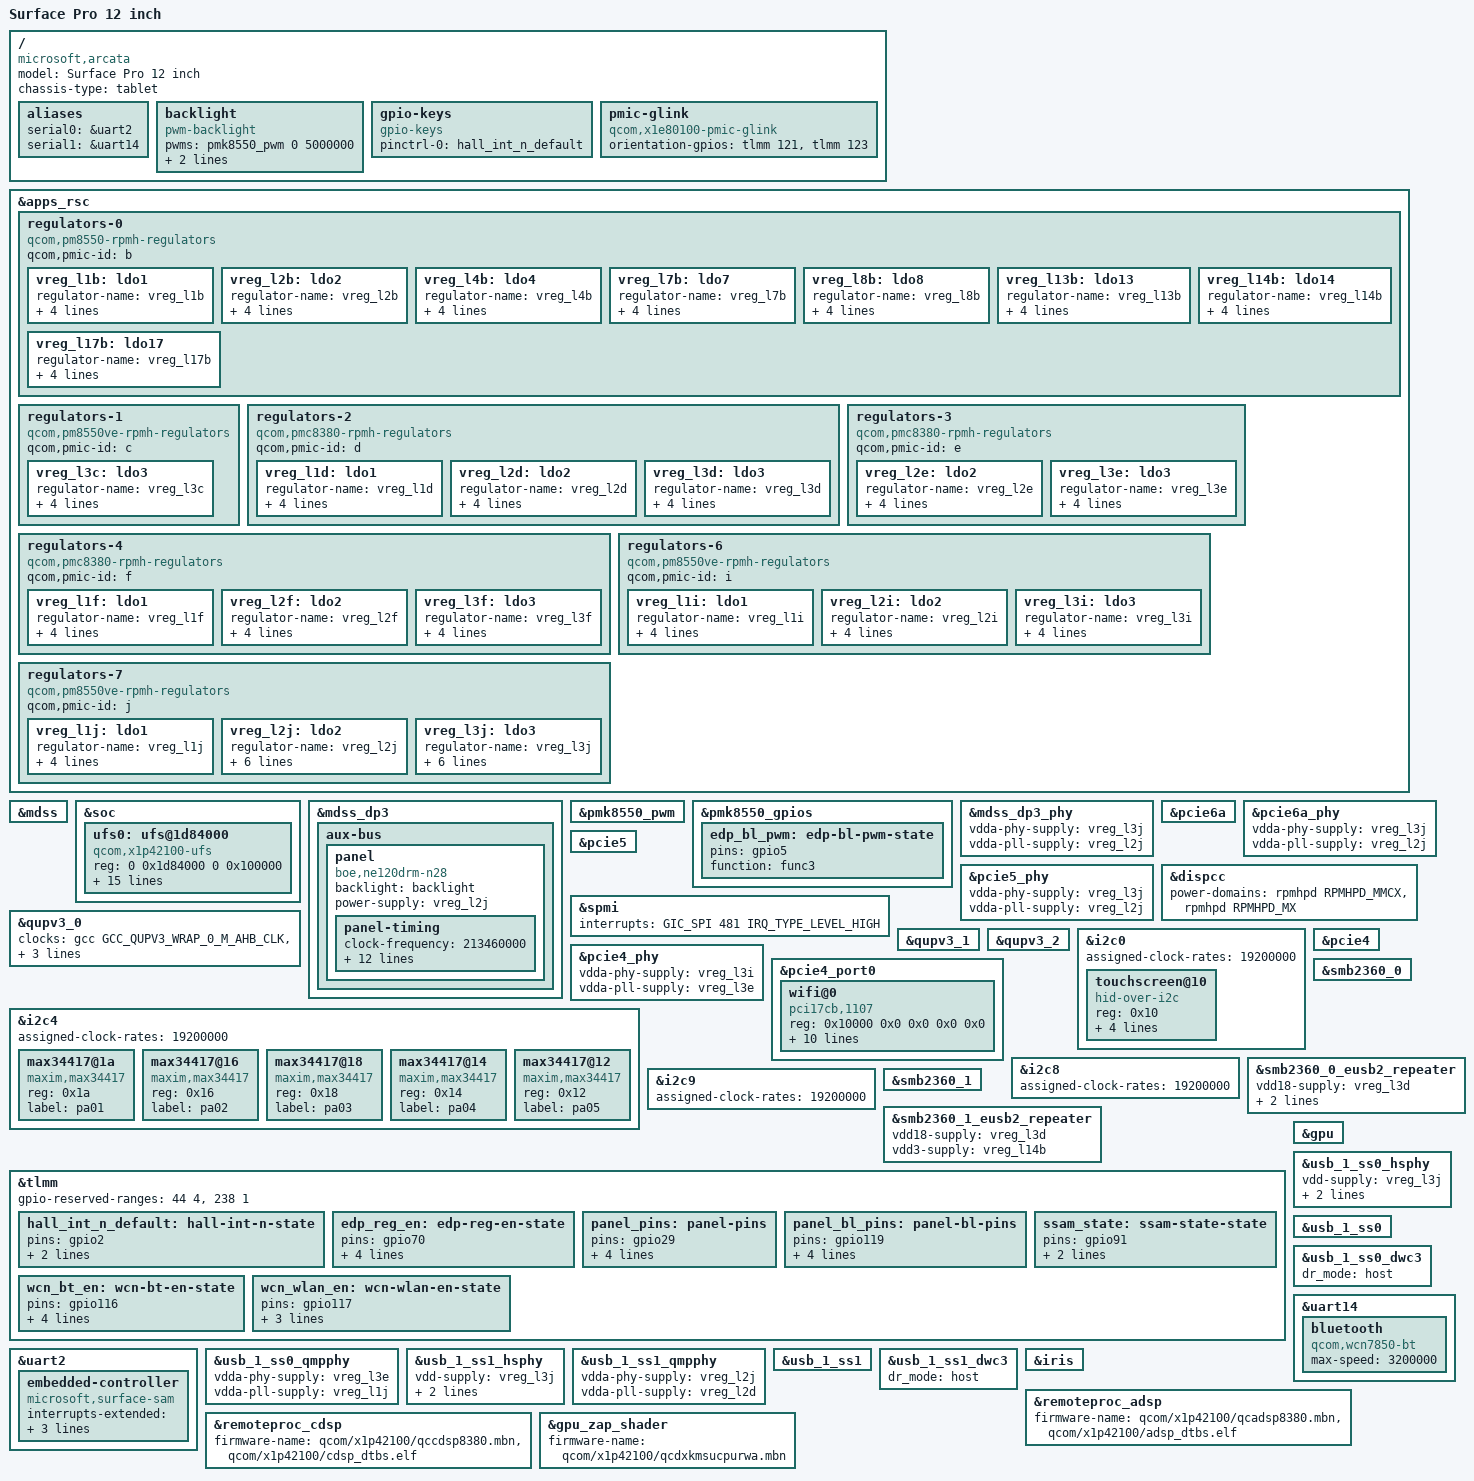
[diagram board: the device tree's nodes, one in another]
// SPDX-License-Identifier: BSD-3-Clause
/*
 * Copyright (c) 2023 Qualcomm Innovation Center, Inc. All rights reserved.
 * Copyright (c) 2024, Xilin Wu <wuxilin123@gmail.com>
 * Copyright (c) 2025 Dale Whinham <daleyo@gmail.com>
 * Copyright (c) 2025 Harrison Vanderbyl <harrison.vanderbyl@gmail.com>
 */

/dts-v1/;

#include <dt-bindings/gpio/gpio.h>
#include <dt-bindings/input/gpio-keys.h>
#include <dt-bindings/input/input.h>
#include <dt-bindings/pinctrl/qcom,pmic-gpio.h>
#include <dt-bindings/regulator/qcom,rpmh-regulator.h>

#include "x1p42100.dtsi"
#include "x1e80100-pmics.dtsi"



/ {
	model = "Surface Pro 12 inch";
	compatible = "microsoft,arcata", "qcom,x1p42100";
	chassis-type = "tablet";

	aliases {
		serial0 = &uart2;
		serial1 = &uart14;
	};
	
	backlight: backlight {
		compatible = "pwm-backlight";
		pwms = <&pmk8550_pwm 0 5000000>;
		enable-gpios = <&pmc8380_3_gpios 4 GPIO_ACTIVE_HIGH>;

		pinctrl-0 = <&panel_bl_pins>, <&edp_bl_pwm>;
		pinctrl-names = "default";

	};

	gpio-keys {
		compatible = "gpio-keys";

		pinctrl-0 = <&hall_int_n_default>;
		pinctrl-names = "default";

	};


	pmic-glink {
		compatible = "qcom,x1e80100-pmic-glink",
			     "qcom,pmic-glink";
		#address-cells = <1>;
		#size-cells = <0>;
		orientation-gpios = <&tlmm 121 GPIO_ACTIVE_HIGH>,
				    <&tlmm 123 GPIO_ACTIVE_HIGH>;

	
	
	
	};


	
};



&apps_rsc {
	regulators-0 {
		compatible = "qcom,pm8550-rpmh-regulators";
		qcom,pmic-id = "b";

		vreg_l1b: ldo1 {
			regulator-name = "vreg_l1b";
			regulator-min-microvolt = <1800000>;
			regulator-max-microvolt = <1800000>;
			regulator-initial-mode = <RPMH_REGULATOR_MODE_HPM>;
		};

		vreg_l2b: ldo2 {
			regulator-name = "vreg_l2b";
			regulator-min-microvolt = <3072000>;
			regulator-max-microvolt = <3072000>;
			regulator-initial-mode = <RPMH_REGULATOR_MODE_HPM>;
		};

		vreg_l4b: ldo4 {
			regulator-name = "vreg_l4b";
			regulator-min-microvolt = <1800000>;
			regulator-max-microvolt = <1800000>;
			regulator-initial-mode = <RPMH_REGULATOR_MODE_HPM>;
		};
		vreg_l7b: ldo7 {
			regulator-name = "vreg_l7b";
			regulator-min-microvolt = <2800000>;
			regulator-max-microvolt = <2800000>;
			regulator-initial-mode = <RPMH_REGULATOR_MODE_HPM>;
		};

		vreg_l8b: ldo8 {
			regulator-name = "vreg_l8b";
			regulator-min-microvolt = <3072000>;
			regulator-max-microvolt = <3072000>;
			regulator-initial-mode = <RPMH_REGULATOR_MODE_HPM>;
		};


		vreg_l13b: ldo13 {
			regulator-name = "vreg_l13b";
			regulator-min-microvolt = <3072000>;
			regulator-max-microvolt = <3072000>;
			regulator-initial-mode = <RPMH_REGULATOR_MODE_HPM>;
		};

		vreg_l14b: ldo14 {
			regulator-name = "vreg_l14b";
			regulator-min-microvolt = <3072000>;
			regulator-max-microvolt = <3072000>;
			regulator-initial-mode = <RPMH_REGULATOR_MODE_HPM>;
		};

		vreg_l17b: ldo17 {
			regulator-name = "vreg_l17b";
			regulator-min-microvolt = <2800000>; /* Assuming a common voltage */
			regulator-max-microvolt = <2800000>; /* Assuming a common voltage */
			regulator-initial-mode = <RPMH_REGULATOR_MODE_HPM>;
		};
	};

	regulators-1 {
		compatible = "qcom,pm8550ve-rpmh-regulators";
		qcom,pmic-id = "c";

		vreg_l3c: ldo3 {
			regulator-name = "vreg_l3c";
			regulator-min-microvolt = <912000>;
			regulator-max-microvolt = <912000>;
			regulator-initial-mode = <RPMH_REGULATOR_MODE_HPM>;
		};
	};

	regulators-2 {
		compatible = "qcom,pmc8380-rpmh-regulators";
		qcom,pmic-id = "d";

		vreg_l1d: ldo1 {
			regulator-name = "vreg_l1d";
			regulator-min-microvolt = <880000>;
			regulator-max-microvolt = <880000>;
			regulator-initial-mode = <RPMH_REGULATOR_MODE_HPM>;
		};
		
		vreg_l2d: ldo2 {
			regulator-name = "vreg_l2d";
			regulator-min-microvolt = <912000>;
			regulator-max-microvolt = <912000>;
			regulator-initial-mode = <RPMH_REGULATOR_MODE_HPM>;
		};

		vreg_l3d: ldo3 {
			regulator-name = "vreg_l3d";
			regulator-min-microvolt = <1800000>;
			regulator-max-microvolt = <1800000>;
			regulator-initial-mode = <RPMH_REGULATOR_MODE_HPM>;
		};
	};

	regulators-3 {
		compatible = "qcom,pmc8380-rpmh-regulators";
		qcom,pmic-id = "e";

		vreg_l2e: ldo2 {
			regulator-name = "vreg_l2e";
			regulator-min-microvolt = <880000>;
			regulator-max-microvolt = <880000>;
			regulator-initial-mode = <RPMH_REGULATOR_MODE_HPM>;
		};

		vreg_l3e: ldo3 {
			regulator-name = "vreg_l3e";
			regulator-min-microvolt = <1200000>;
			regulator-max-microvolt = <1200000>;
			regulator-initial-mode = <RPMH_REGULATOR_MODE_HPM>;
		};
	};

	regulators-4 {
		compatible = "qcom,pmc8380-rpmh-regulators";
		qcom,pmic-id = "f";


		vreg_l1f: ldo1 {
			regulator-name = "vreg_l1f";
			regulator-min-microvolt = <1024000>;
			regulator-max-microvolt = <1024000>;
			regulator-initial-mode = <RPMH_REGULATOR_MODE_HPM>;
		};

		vreg_l2f: ldo2 {
			regulator-name = "vreg_l2f";
			regulator-min-microvolt = <1024000>;
			regulator-max-microvolt = <1024000>;
			regulator-initial-mode = <RPMH_REGULATOR_MODE_HPM>;
		};

		vreg_l3f: ldo3 {
			regulator-name = "vreg_l3f";
			regulator-min-microvolt = <1024000>;
			regulator-max-microvolt = <1024000>;
			regulator-initial-mode = <RPMH_REGULATOR_MODE_HPM>;
		};
	};

	regulators-6 {
		compatible = "qcom,pm8550ve-rpmh-regulators";
		qcom,pmic-id = "i";


		vreg_l1i: ldo1 {
			regulator-name = "vreg_l1i";
			regulator-min-microvolt = <1800000>;
			regulator-max-microvolt = <1800000>;
			regulator-initial-mode = <RPMH_REGULATOR_MODE_HPM>;
		};

		vreg_l2i: ldo2 {
			regulator-name = "vreg_l2i";
			regulator-min-microvolt = <1200000>;
			regulator-max-microvolt = <1200000>;
			regulator-initial-mode = <RPMH_REGULATOR_MODE_HPM>;
		};

		vreg_l3i: ldo3 {
			regulator-name = "vreg_l3i";
			regulator-min-microvolt = <880000>;
			regulator-max-microvolt = <880000>;
			regulator-initial-mode = <RPMH_REGULATOR_MODE_HPM>;
		};
	};

	regulators-7 {
		compatible = "qcom,pm8550ve-rpmh-regulators";
		qcom,pmic-id = "j";


		vreg_l1j: ldo1 {
			regulator-name = "vreg_l1j";
			regulator-min-microvolt = <912000>;
			regulator-max-microvolt = <912000>;
			regulator-initial-mode = <RPMH_REGULATOR_MODE_HPM>;
		};

		vreg_l2j: ldo2 {
			regulator-name = "vreg_l2j";
			regulator-min-microvolt = <1256000>;
			regulator-max-microvolt = <1256000>;
			regulator-initial-mode = <RPMH_REGULATOR_MODE_HPM>;
			regulator-boot-on;
			regulator-always-on;
		};

		vreg_l3j: ldo3 {
			regulator-name = "vreg_l3j";
			regulator-min-microvolt = <880000>;
			regulator-max-microvolt = <880000>;
			regulator-initial-mode = <RPMH_REGULATOR_MODE_HPM>;
			regulator-boot-on;
			regulator-always-on;
		};
	};

	
};

&mdss {
	status = "okay";
	
	
};






&soc {
	ufs0: ufs@1d84000 {
		compatible = "qcom,x1p42100-ufs", "qcom,ufs-qcom";
		reg = <0 0x1d84000 0 0x100000>;
		interrupts = <GIC_SPI 265 IRQ_TYPE_LEVEL_HIGH>; /* Placeholder interrupt */

		clocks = <&gcc GCC_UFS_PHY_AXI_CLK>,
				 <&gcc GCC_UFS_PHY_UNIPRO_CORE_CLK>,
				 <&gcc GCC_UFS_PHY_ICE_CORE_CLK>,
				 <&gcc GCC_AGGRE_UFS_PHY_AXI_CLK>,
				 <&gcc GCC_UFS_PHY_AHB_CLK>,
				 <&gcc GCC_UFS_PHY_PHY_AUX_CLK>,
				 <&gcc GCC_UFS_PHY_TX_SYMBOL_0_CLK>,
				 <&gcc GCC_UFS_PHY_RX_SYMBOL_0_CLK>,
				 <&gcc GCC_UFS_PHY_RX_SYMBOL_1_CLK>,
				 <&tcsr TCSR_UFS_PHY_CLKREF_EN>;
		clock-names = "core_clk", "unipro_core_clk", "ice_core_clk",
					  "aggre_axi_clk", "ahb_clk", "phy_aux_clk",
					  "tx_symbol_0_clk", "rx_symbol_0_clk", "rx_symbol_1_clk",
					  "clkref_en";

		


		vcc-supply = <&vreg_l3j>;
		vcc-max-supply = <&vreg_l17b>;
		vccq-supply = <&vreg_l2i>;
		vccq2-supply = <&vreg_l3e>;

		status = "okay";
	};
};

&mdss_dp3 {
	/delete-property/ #sound-dai-cells;

	status = "okay";

   


        aux-bus {
			panel: panel {
				compatible = "boe,ne120drm-n28", "panel-edp";

				// GPIOs based on display.txt
				
				backlight = <&backlight>;
				power-supply = <&vreg_l2j>;   // J2: 1.256V (corner 7)

				
				// Panel timing based on display.txt
				panel-timing {
					clock-frequency = <213460000>; // Hz
					hactive = <2196>;
					vactive = <1464>;
					hfront-porch = <32>;
					hback-porch = <80>;
					hsync-len = <10>;
					vfront-porch = <8>;
					vback-porch = <12>;
					vsync-len = <4>;
					hsync-active = <0>;
					vsync-active = <0>;
					de-active = <1>;
					pixelclk-active = <0>;
				};

				
			};
		};
	
	
	
	
	};




&pmk8550_pwm {
	status = "okay";
};

&pmk8550_gpios {
	edp_bl_pwm: edp-bl-pwm-state {
		pins = "gpio5";
		function = "func3";
	};
};

&mdss_dp3_phy {
	vdda-phy-supply = <&vreg_l3j>;
	vdda-pll-supply = <&vreg_l2j>;


	status = "okay";
};

&pcie6a {
	status = "okay";
};

&pcie6a_phy {
	vdda-phy-supply = <&vreg_l3j>;
	vdda-pll-supply = <&vreg_l2j>;

	status = "okay";
};

&pcie5 {
	status = "okay";
};
&pcie5_phy {
	vdda-phy-supply = <&vreg_l3j>;
	vdda-pll-supply = <&vreg_l2j>;

	status = "okay";
};


&dispcc {
	power-domains = <&rpmhpd RPMHPD_MMCX>,
					<&rpmhpd RPMHPD_MX>;
	status = "okay";
};

&spmi {
	interrupt-names = "periph_irq";
	interrupts = <GIC_SPI 481 IRQ_TYPE_LEVEL_HIGH>;
};


&qupv3_0 {
	status = "okay";
	clocks = <&gcc GCC_QUPV3_WRAP_0_M_AHB_CLK>,
					<&gcc GCC_QUPV3_WRAP_0_S_AHB_CLK>,
					<&gcc GCC_QUPV3_WRAP0_CORE_CLK>,
					<&gcc GCC_QUPV3_WRAP0_CORE_2X_CLK>;
	clock-names = "m-ahb", "s-ahb", "core", "core2x";
};

&qupv3_1 {
	status = "okay";
};

&qupv3_2 {
	status = "okay";
};

&i2c0 {
	status = "okay";
	// speed 19200000
	assigned-clock-rates = <19200000>;

	touchscreen@10 {
        compatible = "hid-over-i2c";
		reg = <0x10>;
		hid-name = "Surface Pro 12 Touchscreen";
		hid-type = "hidraw";
		hid-quirks = "HID_QUIRK_NOGET";
        wakeup-source;
    };


	  
};

&pcie4 {
	status = "okay";
};

&pcie4_phy {
	vdda-phy-supply = <&vreg_l3i>;
	vdda-pll-supply = <&vreg_l3e>;

	status = "okay";
};

&pcie4_port0 {
	wifi@0 {
		compatible = "pci17cb,1107";
		reg = <0x10000 0x0 0x0 0x0 0x0>;

		vddaon-supply = <&vreg_pmu_aon_0p59>;
		vddwlcx-supply = <&vreg_pmu_wlcx_0p8>;
		vddwlmx-supply = <&vreg_pmu_wlmx_0p85>;
		vddrfacmn-supply = <&vreg_pmu_rfa_cmn>;
		vddrfa0p8-supply = <&vreg_pmu_rfa_0p8>;
		vddrfa1p2-supply = <&vreg_pmu_rfa_1p2>;
		vddrfa1p8-supply = <&vreg_pmu_rfa_1p8>;
		vddpcie0p9-supply = <&vreg_pmu_pcie_0p9>;
		vddpcie1p8-supply = <&vreg_pmu_pcie_1p8>;

		disable-rfkill;
	};
};

&i2c4 {
	
	
	status = "okay";
	assigned-clock-rates = <19200000>;

	max34417@1a {
		compatible = "maxim,max34417";
		reg = <0x1a>;
		label = "pa01";
		status = "okay";
	};

	max34417@16 {
		compatible = "maxim,max34417";
		reg = <0x16>;
		label = "pa02";
		status = "okay";
	};

	max34417@18 {
		compatible = "maxim,max34417";
		reg = <0x18>;
		label = "pa03";
		status = "okay";
	};

	max34417@14 {
		compatible = "maxim,max34417";
		reg = <0x14>;
		label = "pa04";
		status = "okay";
	};

	max34417@12 {
		compatible = "maxim,max34417";
		reg = <0x12>;
		label = "pa05";
		status = "okay";
	};
};

&i2c8 {
	status = "okay";
	assigned-clock-rates = <19200000>;
};

&i2c9 {
	
	status = "okay";
	assigned-clock-rates = <19200000>;
};

&smb2360_0 {
	status = "okay";
};

&smb2360_0_eusb2_repeater {
	vdd18-supply = <&vreg_l3d>;
	vdd3-supply = <&vreg_l2b>;
	vdda-supply = <&vreg_l1d>;                                
};

&smb2360_1 {
	status = "okay";
};

&smb2360_1_eusb2_repeater {
	vdd18-supply = <&vreg_l3d>;
	vdd3-supply = <&vreg_l14b>;
};

&tlmm {
	gpio-reserved-ranges = <44 4>, 
			       <238 1>; 
	hall_int_n_default: hall-int-n-state {
		pins = "gpio2";
		function = "gpio";
		bias-disable;
	};

	edp_reg_en: edp-reg-en-state {
		pins = "gpio70";
		function = "gpio";
		drive-strength = <2>;
		bias-disable;
		output-high;
	};

	 panel_pins: panel-pins {
		pins = "gpio29";
		function = "gpio";
		drive-strength = <2>;
		bias-disable;
		output-low;
	};

	// TLMMGPIO pin 0x77 (119) - Panel backlight enable
	panel_bl_pins: panel-bl-pins {
		pins = "gpio119";
		function = "gpio";
		drive-strength = <2>;
		bias-pull-up;
		output-low;
	};

	

	ssam_state: ssam-state-state {
		pins = "gpio91";
		function = "gpio";
		bias-disable;
	};

	wcn_bt_en: wcn-bt-en-state {
		pins = "gpio116";
		function = "gpio";
		drive-strength = <16>;
		output-low;
		bias-pull-down;
	};

	wcn_wlan_en: wcn-wlan-en-state {
		pins = "gpio117";
		function = "gpio";
		drive-strength = <16>;
		bias-disable;
	};
};

&gpu {
	status = "okay";
};

&uart2 {
	status = "okay";

	embedded-controller {
		compatible = "microsoft,surface-sam";

		interrupts-extended = <&tlmm 91 IRQ_TYPE_EDGE_RISING>;

		current-speed = <4000000>;

		pinctrl-0 = <&ssam_state>;
		pinctrl-names = "default";
	};
};

&usb_1_ss0_hsphy {
	vdd-supply = <&vreg_l3j>;
	vdda12-supply = <&vreg_l2j>;

	phys = <&smb2360_0_eusb2_repeater>;

	status = "okay";
};

&usb_1_ss0_qmpphy {
	vdda-phy-supply = <&vreg_l3e>;
	vdda-pll-supply = <&vreg_l1j>;

	status = "okay";
};

&usb_1_ss0 {
	status = "okay";
};

&usb_1_ss0_dwc3 {
	dr_mode = "host";
};


&uart14 {
	status = "okay";

	bluetooth {
		compatible = "qcom,wcn7850-bt";
		max-speed = <3200000>;

	};
};



&usb_1_ss1_hsphy {
	vdd-supply = <&vreg_l3j>;
	vdda12-supply = <&vreg_l2j>;

	phys = <&smb2360_1_eusb2_repeater>;

	status = "okay";
};

&usb_1_ss1_qmpphy {
	vdda-phy-supply = <&vreg_l2j>;
	vdda-pll-supply = <&vreg_l2d>;

	status = "okay";
};

&usb_1_ss1 {
	status = "okay";
};

&usb_1_ss1_dwc3 {
	dr_mode = "host";
};

&iris {
	status = "okay";

};

&remoteproc_adsp {
	firmware-name = "qcom/x1p42100/qcadsp8380.mbn",
			"qcom/x1p42100/adsp_dtbs.elf";

	status = "okay";
};

&remoteproc_cdsp {
	firmware-name = "qcom/x1p42100/qccdsp8380.mbn",
			"qcom/x1p42100/cdsp_dtbs.elf";

	status = "okay";
};

&gpu_zap_shader {
	firmware-name = "qcom/x1p42100/qcdxkmsucpurwa.mbn";
};
